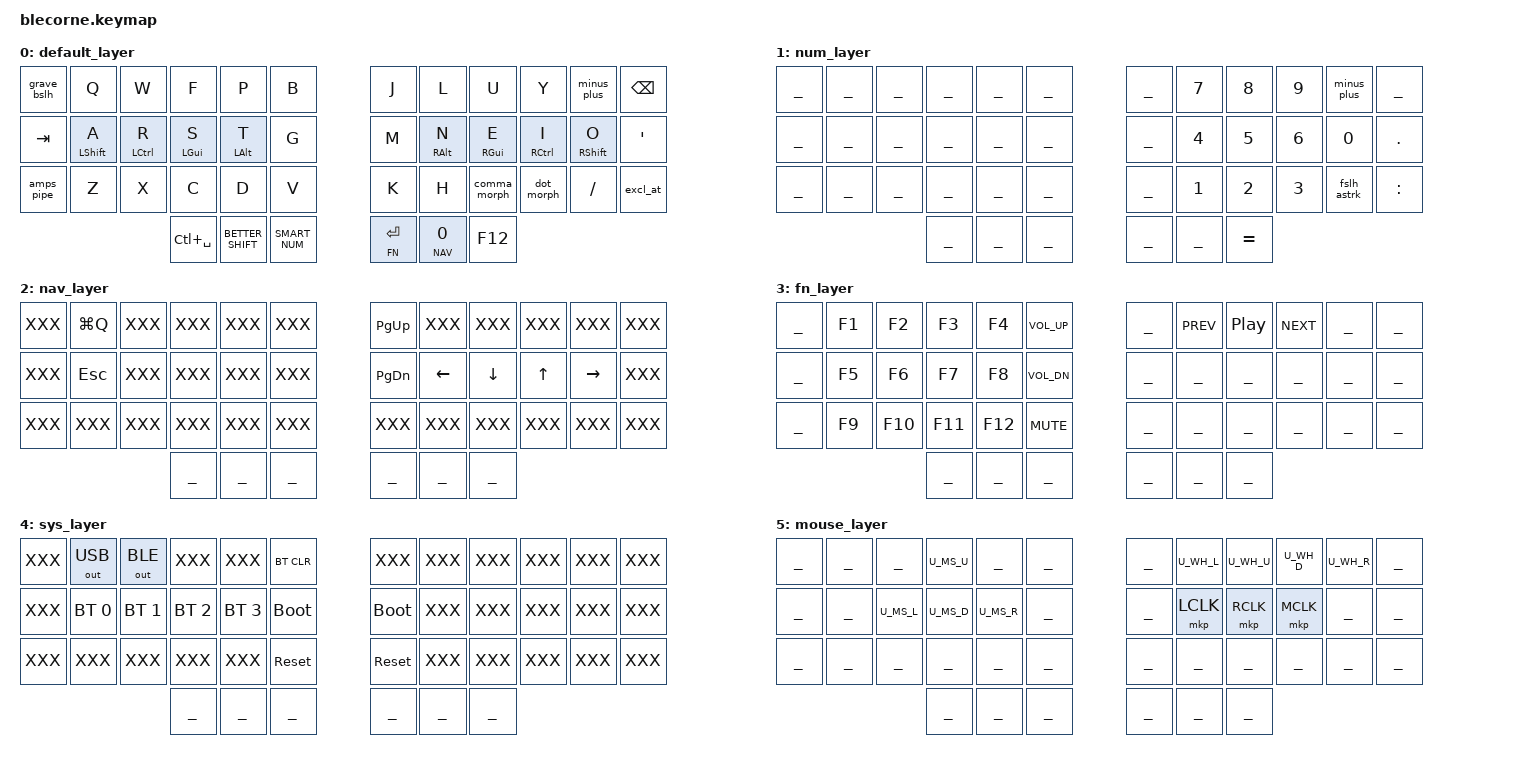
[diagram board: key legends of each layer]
/*
 * Boardsource BLE Corne keymap
 * Colemak-DH with homerow mods, smart layers
 */

#include <behaviors.dtsi>
#include <behaviors/num_word.dtsi>  // Requires zmk-auto-layer module
#include <zmk-helpers/helper.h>     // Requires zmk-helpers module
#include <dt-bindings/zmk/keys.h>
#include <dt-bindings/zmk/bt.h>
#include <dt-bindings/zmk/outputs.h>

#include "settings.dtsi"
#include "mouse.dtsi"
#include "behaviors.dtsi"
#include "combos_horizontal.dtsi"
#include "combos_vertical.dtsi"

/ {
    /* Conditional layer: FN + NUM = SYS */
    conditional_layers {
        compatible = "zmk,conditional-layers";
        sys_layer {
            if-layers = <FN NUM>;
            then-layer = <SYS>;
        };
    };

    keymap {
        compatible = "zmk,keymap";

        default_layer {
            bindings = <
// ╭─────────────┬─────────────┬─────────────┬─────────────┬─────────────┬─────────────╮   ╭─────────────┬─────────────┬─────────────┬─────────────┬─────────────┬─────────────╮
     &grave_bslh   &kp Q         &kp W         &kp F         &kp P         &kp B             &kp J         &kp L         &kp U         &kp Y         &minus_plus   &kp BSPC
// ├─────────────┼─────────────┼─────────────┼─────────────┼─────────────┼─────────────┤   ├─────────────┼─────────────┼─────────────┼─────────────┼─────────────┼─────────────┤
     &kp TAB       &hml LSHFT A  &hml LCTRL R  &hml LGUI S   &hml LALT T   &kp G             &kp M         &hmr RALT N   &hmr RGUI E   &hmr RCTRL I  &hmr RSHFT O  &kp SQT
// ├─────────────┼─────────────┼─────────────┼─────────────┼─────────────┼─────────────┤   ├─────────────┼─────────────┼─────────────┼─────────────┼─────────────┼─────────────┤
     &amps_pipe    &kp Z         &kp X         &kp C         &kp D         &kp V             &kp K         &kp H         &comma_morph  &dot_morph    &kp FSLH      &excl_at
// ╰─────────────┴─────────────┴─────────────┼─────────────┼─────────────┼─────────────┤   ├─────────────┼─────────────┼─────────────┼─────────────┴─────────────┴─────────────╯
                                               &kp LC(SPACE) BETTER_SHIFT  SMART_NUM         &lt FN RET    &lt_spc NAV 0 &kp F12 
//                                           ╰─────────────┴─────────────┴─────────────╯   ╰─────────────┴─────────────┴─────────────╯
            >;
        };

        num_layer {
            bindings = <
              // Most non-number keys need to be &trans to break out of numword.
// ╭─────────────┬─────────────┬─────────────┬─────────────┬─────────────┬─────────────╮   ╭─────────────┬─────────────┬─────────────┬─────────────┬─────────────┬─────────────╮
     ___           ___           ___           ___           ___           ___               ___           &kp N7        &kp N8        &kp N9        &minus_plus   ___ 
// ├─────────────┼─────────────┼─────────────┼─────────────┼─────────────┼─────────────┤   ├─────────────┼─────────────┼─────────────┼─────────────┼─────────────┼─────────────┤
     ___           ___           ___           ___           ___           ___               ___           &kp N4        &kp N5        &kp N6        &kp N0        &kp DOT
// ├─────────────┼─────────────┼─────────────┼─────────────┼─────────────┼─────────────┤   ├─────────────┼─────────────┼─────────────┼─────────────┼─────────────┼─────────────┤
     ___           ___           ___           ___           ___           ___               ___           &kp N1        &kp N2        &kp N3        &fslh_astrk   &kp COLON
// ╰─────────────┴─────────────┴─────────────┼─────────────┼─────────────┼─────────────┤   ├─────────────┼─────────────┼─────────────┼─────────────┴─────────────┴─────────────╯
                                               ___           ___           ___               ___           ___           &kp EQUAL
//                                           ╰─────────────┴─────────────┴─────────────╯   ╰─────────────┴─────────────┴─────────────╯
            >;
        };

        nav_layer {
            bindings = <
// ╭─────────────┬─────────────┬─────────────┬─────────────┬─────────────┬─────────────╮   ╭─────────────┬─────────────┬─────────────┬─────────────┬─────────────┬─────────────╮
     XXX           &kp LG(Q)     XXX           XXX           XXX           XXX               &kp PG_UP     XXX           XXX           XXX           XXX           XXX 
// ├─────────────┼─────────────┼─────────────┼─────────────┼─────────────┼─────────────┤   ├─────────────┼─────────────┼─────────────┼─────────────┼─────────────┼─────────────┤
     XXX           &kp ESC       XXX           XXX           XXX           XXX               &kp PG_DN     &kp LEFT      &kp DOWN      &kp UP        &kp RIGHT     XXX
// ├─────────────┼─────────────┼─────────────┼─────────────┼─────────────┼─────────────┤   ├─────────────┼─────────────┼─────────────┼─────────────┼─────────────┼─────────────┤
     XXX           XXX           XXX           XXX           XXX           XXX               XXX           XXX           XXX           XXX           XXX           XXX
// ╰─────────────┴─────────────┴─────────────┼─────────────┼─────────────┼─────────────┤   ├─────────────┼─────────────┼─────────────┼─────────────┴─────────────┴─────────────╯
                                               ___           ___           ___               ___           ___           ___
//                                           ╰─────────────┴─────────────┴─────────────╯   ╰─────────────┴─────────────┴─────────────╯
            >;
        };

        fn_layer {
            bindings = <
// ╭─────────────┬─────────────┬─────────────┬─────────────┬─────────────┬─────────────╮   ╭─────────────┬─────────────┬─────────────┬─────────────┬─────────────┬─────────────╮
     ___           &kp F1        &kp F2        &kp F3        &kp F4        &kp C_VOL_UP      ___           &kp C_PREV    &kp C_PP      &kp C_NEXT    ___           ___
// ├─────────────┼─────────────┼─────────────┼─────────────┼─────────────┼─────────────┤   ├─────────────┼─────────────┼─────────────┼─────────────┼─────────────┼─────────────┤
     ___           &kp F5        &kp F6        &kp F7        &kp F8        &kp C_VOL_DN      ___           ___           ___           ___           ___           ___
// ├─────────────┼─────────────┼─────────────┼─────────────┼─────────────┼─────────────┤   ├─────────────┼─────────────┼─────────────┼─────────────┼─────────────┼─────────────┤
     ___           &kp F9        &kp F10       &kp F11       &kp F12       &kp C_MUTE        ___           ___           ___           ___           ___           ___
// ╰─────────────┴─────────────┴─────────────┼─────────────┼─────────────┼─────────────┤   ├─────────────┼─────────────┼─────────────┼─────────────┴─────────────┴─────────────╯
                                               ___           ___           ___               ___           ___           ___
//                                           ╰─────────────┴─────────────┴─────────────╯   ╰─────────────┴─────────────┴─────────────╯
            >;
        };

        sys_layer {
            bindings = <
// ╭─────────────┬─────────────┬─────────────┬─────────────┬─────────────┬─────────────╮   ╭─────────────┬─────────────┬─────────────┬─────────────┬─────────────┬─────────────╮
     XXX           &out OUT_USB  &out OUT_BLE  XXX           XXX           &bt BT_CLR        XXX           XXX           XXX           XXX           XXX           XXX
// ├─────────────┼─────────────┼─────────────┼─────────────┼─────────────┼─────────────┤   ├─────────────┼─────────────┼─────────────┼─────────────┼─────────────┼─────────────┤
     XXX           &bt BT_SEL 0  &bt BT_SEL 1  &bt BT_SEL 2  &bt BT_SEL 3  &bootloader       &bootloader   XXX           XXX           XXX           XXX           XXX
// ├─────────────┼─────────────┼─────────────┼─────────────┼─────────────┼─────────────┤   ├─────────────┼─────────────┼─────────────┼─────────────┼─────────────┼─────────────┤
     XXX           XXX           XXX           XXX           XXX           &sys_reset        &sys_reset    XXX           XXX           XXX           XXX           XXX
// ╰─────────────┴─────────────┴─────────────┼─────────────┼─────────────┼─────────────┤   ├─────────────┼─────────────┼─────────────┼─────────────┴─────────────┴─────────────╯
                                               ___           ___           ___               ___           ___           ___
//                                           ╰─────────────┴─────────────┴─────────────╯   ╰─────────────┴─────────────┴─────────────╯
            >;
        };

        mouse_layer {
            bindings = <
// ╭─────────────┬─────────────┬─────────────┬─────────────┬─────────────┬─────────────╮   ╭─────────────┬─────────────┬─────────────┬─────────────┬─────────────┬─────────────╮
     ___           ___           ___           U_MS_U        ___           ___               ___           U_WH_L        U_WH_U        U_WH_D        U_WH_R        ___
// ├─────────────┼─────────────┼─────────────┼─────────────┼─────────────┼─────────────┤   ├─────────────┼─────────────┼─────────────┼─────────────┼─────────────┼─────────────┤
     ___           ___           U_MS_L        U_MS_D        U_MS_R        ___               ___           &mkp LCLK     &mkp RCLK     &mkp MCLK     ___           ___
// ├─────────────┼─────────────┼─────────────┼─────────────┼─────────────┼─────────────┤   ├─────────────┼─────────────┼─────────────┼─────────────┼─────────────┼─────────────┤
     ___           ___           ___           ___           ___           ___               ___           ___           ___           ___           ___           ___
// ╰─────────────┴─────────────┴─────────────┼─────────────┼─────────────┼─────────────┤   ├─────────────┼─────────────┼─────────────┼─────────────┴─────────────┴─────────────╯
                                               ___           ___           ___               ___           ___           ___
//                                           ╰─────────────┴─────────────┴─────────────╯   ╰─────────────┴─────────────┴─────────────╯
            >;
        };
    };
};
